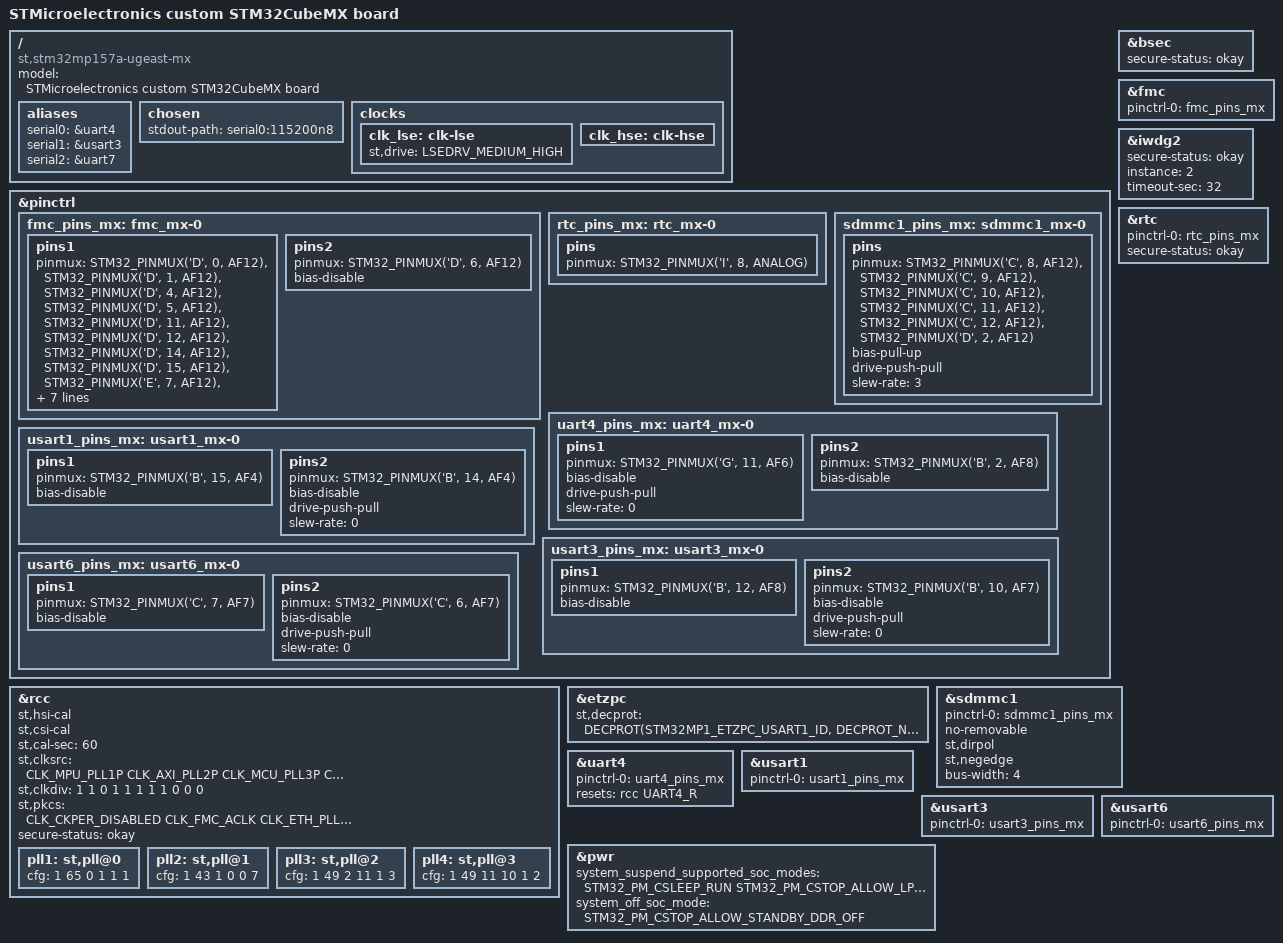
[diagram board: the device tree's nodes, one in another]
/* SPDX-License-Identifier: (GPL-2.0+ OR BSD-3-Clause) */
/*
 * Copyright (C) STMicroelectronics 2019 - All Rights Reserved
 * Author: STM32CubeMX code generation for STMicroelectronics.
 */

/* MPU: 800Mhz */
/* DDR: 1G */

/dts-v1/;
#include <dt-bindings/clock/stm32mp1-clksrc.h>
#include <dt-bindings/power/stm32mp1-power.h>

#include "stm32mp15-1G-mx.h"

#include "stm32mp157c.dtsi"
#include "stm32mp157cac-pinctrl.dtsi"
#include "stm32mp15-ddr.dtsi"
#include "stm32mp157c-security.dtsi"

/* USER CODE BEGIN includes */
/* USER CODE END includes */

/ {
	model = "STMicroelectronics custom STM32CubeMX board";
	compatible = "st,stm32mp157a-ugeast-mx", "st,stm32mp157";

	/* USER CODE BEGIN root */

	aliases {
		serial0 = &uart4;
		serial1 = &usart3;
		serial2 = &uart7;
	};

	chosen {
		stdout-path = "serial0:115200n8";
	};

	/* USER CODE END root */

clocks {
    /* USER CODE BEGIN clocks */
    /* USER CODE END clocks */

    clk_lse: clk-lse {
        /* USER CODE BEGIN clocks */
        /* USER CODE END clocks */
        st,drive=<LSEDRV_MEDIUM_HIGH>;
    };
    clk_hse: clk-hse {
        /* USER CODE BEGIN clocks */
        /* USER CODE END clocks */
    };
};

}; /*root*/

&pinctrl {
    fmc_pins_mx: fmc_mx-0 {
        pins1 {
            pinmux = <STM32_PINMUX('D', 0, AF12)>, /* FMC_D2 */
                     <STM32_PINMUX('D', 1, AF12)>, /* FMC_D3 */
                     <STM32_PINMUX('D', 4, AF12)>, /* FMC_NOE */
                     <STM32_PINMUX('D', 5, AF12)>, /* FMC_NWE */
                     <STM32_PINMUX('D', 11, AF12)>, /* FMC_CLE */
                     <STM32_PINMUX('D', 12, AF12)>, /* FMC_ALE */
                     <STM32_PINMUX('D', 14, AF12)>, /* FMC_D0 */
                     <STM32_PINMUX('D', 15, AF12)>, /* FMC_D1 */
                     <STM32_PINMUX('E', 7, AF12)>, /* FMC_D4 */
                     <STM32_PINMUX('E', 8, AF12)>, /* FMC_D5 */
                     <STM32_PINMUX('E', 9, AF12)>, /* FMC_D6 */
                     <STM32_PINMUX('E', 10, AF12)>, /* FMC_D7 */
                     <STM32_PINMUX('G', 9, AF12)>; /* FMC_NCE */
            bias-disable;
            drive-push-pull;
            slew-rate = <1>;
        };
        pins2 {
            pinmux = <STM32_PINMUX('D', 6, AF12)>; /* FMC_NWAIT */
            bias-disable;
        };
    };
    rtc_pins_mx: rtc_mx-0 {
        pins {
            pinmux = <STM32_PINMUX('I', 8, ANALOG)>; /* RTC_LSCO */
        };
    };
    sdmmc1_pins_mx: sdmmc1_mx-0 {
        pins {
            pinmux = <STM32_PINMUX('C', 8, AF12)>, /* SDMMC1_D0 */
                     <STM32_PINMUX('C', 9, AF12)>, /* SDMMC1_D1 */
                     <STM32_PINMUX('C', 10, AF12)>, /* SDMMC1_D2 */
                     <STM32_PINMUX('C', 11, AF12)>, /* SDMMC1_D3 */
                     <STM32_PINMUX('C', 12, AF12)>, /* SDMMC1_CK */
                     <STM32_PINMUX('D', 2, AF12)>; /* SDMMC1_CMD */
            bias-pull-up;
            drive-push-pull;
            slew-rate = <3>;
        };
    };
    uart4_pins_mx: uart4_mx-0 {
        pins1 {
            pinmux = <STM32_PINMUX('G', 11, AF6)>; /* UART4_TX */
            bias-disable;
            drive-push-pull;
            slew-rate = <0>;
        };
        pins2 {
            pinmux = <STM32_PINMUX('B', 2, AF8)>; /* UART4_RX */
            bias-disable;
        };
    };
    usart1_pins_mx: usart1_mx-0 {
        pins1 {
            pinmux = <STM32_PINMUX('B', 15, AF4)>; /* USART1_RX */
            bias-disable;
        };
        pins2 {
            pinmux = <STM32_PINMUX('B', 14, AF4)>; /* USART1_TX */
            bias-disable;
            drive-push-pull;
            slew-rate = <0>;
        };
    };
    usart3_pins_mx: usart3_mx-0 {
        pins1 {
            pinmux = <STM32_PINMUX('B', 12, AF8)>; /* USART3_RX */
            bias-disable;
        };
        pins2 {
            pinmux = <STM32_PINMUX('B', 10, AF7)>; /* USART3_TX */
            bias-disable;
            drive-push-pull;
            slew-rate = <0>;
        };
    };
    usart6_pins_mx: usart6_mx-0 {
        pins1 {
            pinmux = <STM32_PINMUX('C', 7, AF7)>; /* USART6_RX */
            bias-disable;
        };
        pins2 {
            pinmux = <STM32_PINMUX('C', 6, AF7)>; /* USART6_TX */
            bias-disable;
            drive-push-pull;
            slew-rate = <0>;
        };
    };
};


&rcc {
    st,hsi-cal;
    st,csi-cal;
    st,cal-sec = <60>;
    st,clksrc = <
        CLK_MPU_PLL1P
        CLK_AXI_PLL2P
        CLK_MCU_PLL3P
        CLK_PLL12_HSE
        CLK_PLL3_HSE
        CLK_PLL4_HSE
        CLK_RTC_LSE
        CLK_MCO1_DISABLED
        CLK_MCO2_DISABLED
    >;
    st,clkdiv = <
        1         /*MPU*/
        1         /*AXI*/
        0         /*MCU*/
        1         /*APB1*/
        1         /*APB2*/
        1         /*APB3*/
        1         /*APB4*/
        1         /*APB5*/
        0         /*RTC*/
        0         /*MCO1*/
        0         /*MCO2*/
    >;
    st,pkcs = <
        CLK_CKPER_DISABLED
        CLK_FMC_ACLK
        CLK_ETH_PLL3Q
        CLK_SDMMC12_HSI
        CLK_STGEN_HSI
        CLK_USBPHY_HSE
        CLK_SPI2S1_DISABLED
        CLK_SPI2S23_DISABLED
        CLK_SPI45_DISABLED
        CLK_SPI6_DISABLED
        CLK_I2C46_CSI
        CLK_SDMMC3_HCLK2
        CLK_USBO_USBPHY
        CLK_ADC_PLL3Q
        CLK_CEC_DISABLED
        CLK_I2C12_HSI
        CLK_I2C35_DISABLED
        CLK_UART1_HSI
        CLK_UART24_HSE
        CLK_UART35_PCLK1
        CLK_UART6_PCLK2
        CLK_UART78_PCLK1
        CLK_SPDIF_DISABLED
        CLK_FDCAN_HSE
        CLK_SAI1_DISABLED
        CLK_SAI2_PLL3Q
        CLK_SAI3_DISABLED
        CLK_SAI4_DISABLED
        CLK_RNG1_CSI
        CLK_LPTIM1_DISABLED
        CLK_LPTIM23_DISABLED
        CLK_LPTIM45_DISABLED
    >;
    pll1:st,pll@0 { /* MPU = 800MHz */
        cfg = < 1 65 0 1 1 1>;
    };
    pll2:st,pll@1 {
        cfg = < 1 43 1 0 0 7>;
    };
    pll3:st,pll@2 {
        cfg = < 1 49 2 11 1 3>;
    };
    pll4:st,pll@3 {
        cfg = < 1 49 11 10 1 2>;
    };
};

&etzpc {
	st,decprot = <
		DECPROT(STM32MP1_ETZPC_USART1_ID, DECPROT_NS_RW, DECPROT_UNLOCK)
		DECPROT(STM32MP1_ETZPC_USART3_ID, DECPROT_NS_RW, DECPROT_UNLOCK)
		DECPROT(STM32MP1_ETZPC_UART4_ID, DECPROT_NS_RW, DECPROT_UNLOCK)
		DECPROT(STM32MP1_ETZPC_UART7_ID, DECPROT_NS_RW, DECPROT_UNLOCK)
		DECPROT(STM32MP1_ETZPC_UART8_ID, DECPROT_NS_RW, DECPROT_UNLOCK)
		DECPROT(STM32MP1_ETZPC_SPI6_ID, DECPROT_NS_RW, DECPROT_UNLOCK)
		DECPROT(STM32MP1_ETZPC_I2C4_ID, DECPROT_NS_RW, DECPROT_UNLOCK)
		DECPROT(STM32MP1_ETZPC_I2C6_ID, DECPROT_NS_RW, DECPROT_UNLOCK)
		DECPROT(STM32MP1_ETZPC_RNG1_ID, DECPROT_NS_RW, DECPROT_UNLOCK)
		DECPROT(STM32MP1_ETZPC_HASH1_ID, DECPROT_NS_RW, DECPROT_UNLOCK)
		DECPROT(STM32MP1_ETZPC_CRYP1_ID, DECPROT_NS_RW, DECPROT_UNLOCK)
		DECPROT(STM32MP1_ETZPC_ETH_ID,	DECPROT_NS_RW,	DECPROT_UNLOCK)
		DECPROT(STM32MP1_ETZPC_VREFBUF_ID, DECPROT_NS_RW, DECPROT_UNLOCK)
        DECPROT(STM32MP1_ETZPC_SDMMC3_ID, DECPROT_NS_RW, DECPROT_UNLOCK)
	>;
};

&bsec{
    status = "okay";
    secure-status = "okay";

    /* USER CODE BEGIN bsec */
    /* USER CODE END bsec */
};

&fmc{
    pinctrl-names = "default";
    pinctrl-0 = <&fmc_pins_mx>;
    status = "okay";

    /* USER CODE BEGIN fmc */
    /* USER CODE END fmc */
};

&iwdg2{
    status = "okay";
    secure-status = "okay";

    /* USER CODE BEGIN iwdg2 */
    instance = <2>;
    timeout-sec = <32>;
    /* USER CODE END iwdg2 */
};

&rcc{
    status = "okay";
    secure-status = "okay";

    /* USER CODE BEGIN rcc */
    /* USER CODE END rcc */
};

&rtc{
    pinctrl-names = "default";
    pinctrl-0 = <&rtc_pins_mx>;
    status = "okay";
    secure-status = "okay";

    /* USER CODE BEGIN rtc */
    /* USER CODE END rtc */
};

&sdmmc1{
    pinctrl-names = "default";
    pinctrl-0 = <&sdmmc1_pins_mx>;
    status = "okay";

    /* USER CODE BEGIN sdmmc1 */
    no-removable;
    st,dirpol;
    st,negedge;
    bus-width=<4>;
    /* USER CODE END sdmmc1 */
};

&uart4{
    pinctrl-names = "default";
    pinctrl-0 = <&uart4_pins_mx>;
    status = "okay";

    /* USER CODE BEGIN uart4 */
    resets = <&rcc UART4_R>;
    /* USER CODE END uart4 */
};

&usart1{
    pinctrl-names = "default";
    pinctrl-0 = <&usart1_pins_mx>;
	status = "okay";

    /* USER CODE BEGIN usart1 */
    /* USER CODE END usart1 */
};

&usart3{
    pinctrl-names = "default";
    pinctrl-0 = <&usart3_pins_mx>;
    status = "okay";

    /* USER CODE BEGIN usart3 */
    /* USER CODE END usart3 */
};

&usart6{
    pinctrl-names = "default";
    pinctrl-0 = <&usart6_pins_mx>;
    status = "okay";

    /* USER CODE BEGIN usart6 */
    /* USER CODE END usart6 */
};

/* USER CODE BEGIN addons */
&pwr {
	system_suspend_supported_soc_modes = <
		STM32_PM_CSLEEP_RUN
		STM32_PM_CSTOP_ALLOW_LP_STOP
		STM32_PM_CSTOP_ALLOW_STANDBY_DDR_SR
	>;

	system_off_soc_mode = <STM32_PM_CSTOP_ALLOW_STANDBY_DDR_OFF>;
};
/* USER CODE END addons */

